# LPC5411x register map
File version: 0.3
CPU: CM4 r0p0, little endian, MPU, FPU, 3 interrupt priority bits
Registers are 32-bit, read-write, reset 0x0 unless marked. A register's access mark holds for its fields unless they carry their own. Offsets are from the block's base; [hi:lo] are bit positions; {n}, {i} and the like mark numbered series; 'fields as' and 'values as' point back to an identical list.

## IOCON — I/O pin configuration
Base 0x40001000
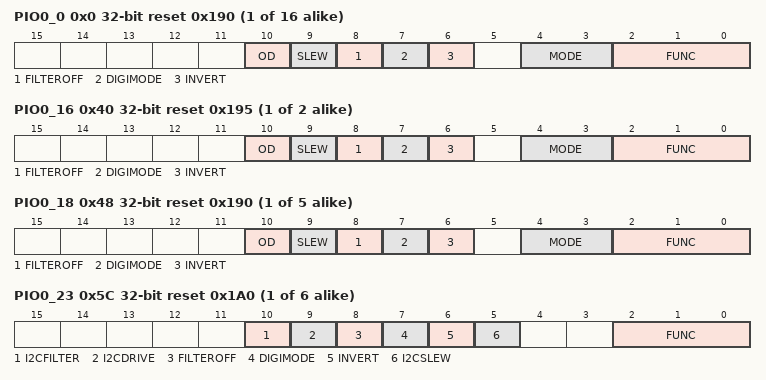
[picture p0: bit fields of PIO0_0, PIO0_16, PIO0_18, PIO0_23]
{0x0+4i} PIO0_{i} (i=0..15) reset 0x190 — Digital I/O control for port 0 pins PIO0_0 to PIO0_15.
  [10] OD — Controls open-drain mode.
    0=NORMAL (Normal. Normal push-pull output); 1=OPEN_DRAIN (Open-drain. Simulated open-drain output (high drive disabled))
  [9] SLEW — Driver slew rate.
    0=STANDARD_MODE (Standard mode, output slew rate control is enabled. More outputs can be switched simultaneously.); 1=FAST_MODE (Fast mode, slew rate control is disabled. Refer to the appropriate specific device data sheet for details.)
  [8] FILTEROFF — Controls input glitch filter.
    0=FILTER_ENABLED (Filter enabled. Noise pulses below approximately 10 ns are filtered out); 1=FILTER_DISABLED (Filter disabled. No input filtering is done)
  [7] DIGIMODE — Select Analog/Digital mode.
    0=ANALOG_MODE; 1=DIGITAL_MODE
  [6] INVERT — Input polarity.
    0=DISABLED (Disabled. Input function is not inverted.); 1=ENABLED (Enabled. Input is function inverted.)
  [4:3] MODE — Selects function mode (on-chip pull-up/pull-down resistor control).
    0=INACTIVE (Inactive. Inactive (no pull-down/pull-up resistor enabled).); 1=PULL_DOWN (Pull-down. Pull-down resistor enabled.); 2=PULL_UP (Pull-up. Pull-up resistor enabled.); 3=REPEATER (Repeater. Repeater mode.)
  [2:0] FUNC — Selects pin function.
{0x0+4i} PIO0_{i} (i=16..17) reset 0x195 — Digital I/O control for port 0 pins PIO0_16 to PIO0_17.
  fields as PIO0_0
{0x0+4i} PIO0_{i} (i=18..22) reset 0x190 — Digital I/O control for port 0 pins PIO0_18 to PIO0_22.
  fields as PIO0_0
{0x0+4i} PIO0_{i} (i=23..28) reset 0x1A0 — Digital I/O control for port 0 pins PIO0_23 to PIO0_28. These pins support I2C with true open-drain, drive and filtering for modes up to Fast-mode Plus.
  [10] I2CFILTER — Configures I2C features for standard mode, fast mode, and Fast Mode Plus operation.
    0=ENABLED (Enabled. I2C 50 ns glitch filter enabled.); 1=DISABLED (Disabled. I2C 50 ns glitch filter disabled.)
  [9] I2CDRIVE — Controls the current sink capability of the pin.
    0=LOW_DRIVE (Low drive. Output drive sink is 4 mA. This is sufficient for standard and fast mode I2C.); 1=HIGH_DRIVE (High drive. Output drive sink is 20 mA. This is needed for Fast Mode Plus I 2C. Refer to the appropriate specific device data sheet for details.)
  [8] FILTEROFF — Controls input glitch filter.
    values as PIO0_0.FILTEROFF
  [7] DIGIMODE — Select Analog/Digital mode.
    0=ANALOG_MODE; 1=DIGITAL_MODE
  [6] INVERT — Input polarity.
    values as PIO0_0.INVERT
  [5] I2CSLEW — Controls slew rate of I2C pad.
    0=I2C_MODE; 1=GPIO_MODE
  [2:0] FUNC — Selects pin function.
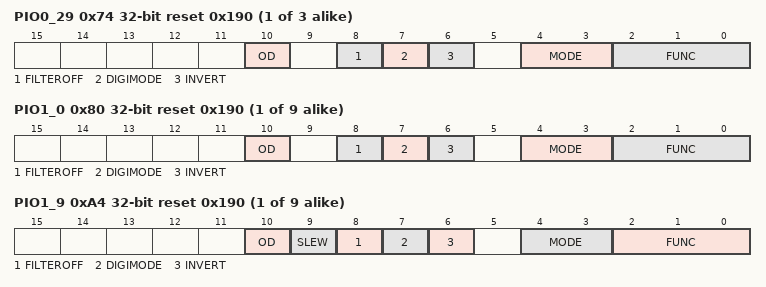
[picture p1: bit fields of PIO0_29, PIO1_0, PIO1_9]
{0x0+4i} PIO0_{i} (i=29..31) reset 0x190 — Digital I/O control for port 0 pins PIO0_29 to PIO0_31. These pins include an ADC input.
  [10] OD — Controls open-drain mode.
    values as PIO0_0.OD
  [8] FILTEROFF — Controls input glitch filter.
    values as PIO0_0.FILTEROFF
  [7] DIGIMODE — Select Analog/Digital mode.
    0=ANALOG_MODE; 1=DIGITAL_MODE
  [6] INVERT — Input polarity.
    values as PIO0_0.INVERT
  [4:3] MODE — Selects function mode (on-chip pull-up/pull-down resistor control).
    values as PIO0_0.MODE
  [2:0] FUNC — Selects pin function.
{0x80+4i} PIO1_{i} (i=0..8) reset 0x190 — Digital I/O control for port 1 pins PIO0_0 to PIO0_8. These pins include an ADC input.
  fields as PIO0_29
{0x80+4i} PIO1_{i} (i=9..17) reset 0x190 — Digital I/O control for port 1 pins PIO1_9 to PIO1_17.
  fields as PIO0_0

## UTICK — Micro-tick timer
Base 0x4000E000
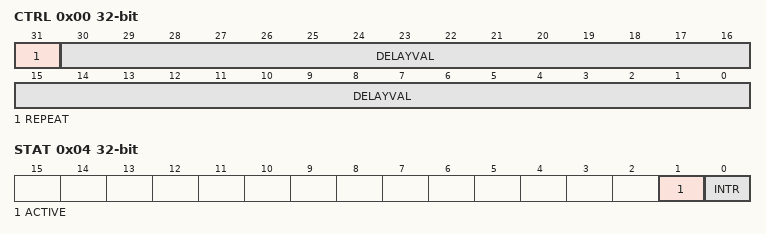
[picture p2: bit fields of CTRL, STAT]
0x00 CTRL — Control register.
  [31] REPEAT — Repeat delay. 0 = One-time delay. 1 = Delay repeats continuously.
  [30:0] DELAYVAL — Tick interval value. The delay will be equal to DELAYVAL + 1 periods of the timer clock. The minimum usable value is 1, for a delay of 2 timer clocks. A value of 0 stops the timer.
0x04 STAT — Status register.
  [1] ACTIVE — Active flag. 0 = The Micro-Tick Timer is stopped. 1 = The Micro-Tick Timer is currently active.
  [0] INTR — Interrupt flag. 0 = No interrupt is pending. 1 = An interrupt is pending. A write of any value to this register clears this flag.
